# BL808 register map
File version: 0.1
Registers are access not given, no defined reset value unless marked. A register's access mark holds for its fields unless they carry their own. Offsets are from the block's base; [hi:lo] are bit positions.

## MM_GLB_CLK_RST
Base 0x30007000
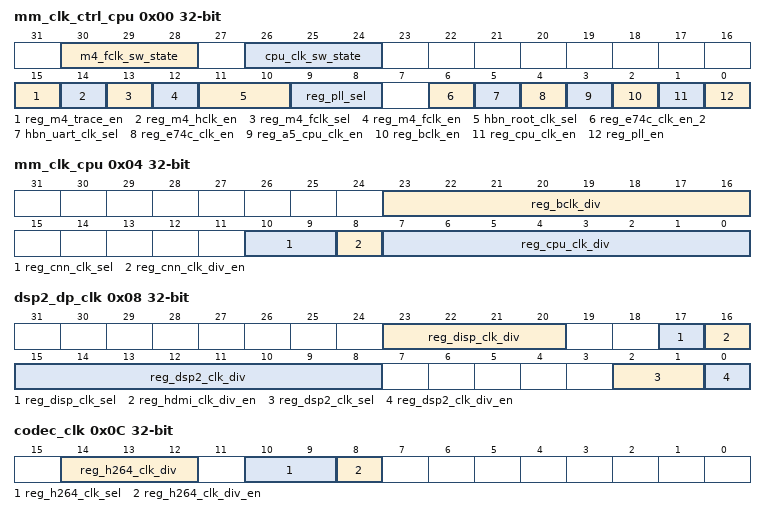
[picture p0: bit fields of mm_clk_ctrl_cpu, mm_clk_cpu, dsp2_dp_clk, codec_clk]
0x00 mm_clk_ctrl_cpu
  [30:28] m4_fclk_sw_state ro, [26:24] cpu_clk_sw_state ro, [15] reg_m4_trace_en rw, [14] reg_m4_hclk_en rw, [13] reg_m4_fclk_sel rw, [12] reg_m4_fclk_en rw, [11:10] hbn_root_clk_sel rw, [9:8] reg_pll_sel rw, [6] reg_e74c_clk_en_2 rw, [5] hbn_uart_clk_sel rw, [4] reg_e74c_clk_en rw, [3] reg_a5_cpu_clk_en rw, [2] reg_bclk_en rw, [1] reg_cpu_clk_en rw, [0] reg_pll_en rw
0x04 mm_clk_cpu
  [23:16] reg_bclk_div rw, [10:9] reg_cnn_clk_sel rw, [8] reg_cnn_clk_div_en rw, [7:0] reg_cpu_clk_div rw
0x08 dsp2_dp_clk
  [23:20] reg_disp_clk_div rw, [17] reg_disp_clk_sel rw, [16] reg_hdmi_clk_div_en rw, [15:8] reg_dsp2_clk_div rw, [2:1] reg_dsp2_clk_sel rw, [0] reg_dsp2_clk_div_en rw
0x0C codec_clk
  [14:12] reg_h264_clk_div, [10:9] reg_h264_clk_sel rw, [8] reg_h264_clk_div_en rw
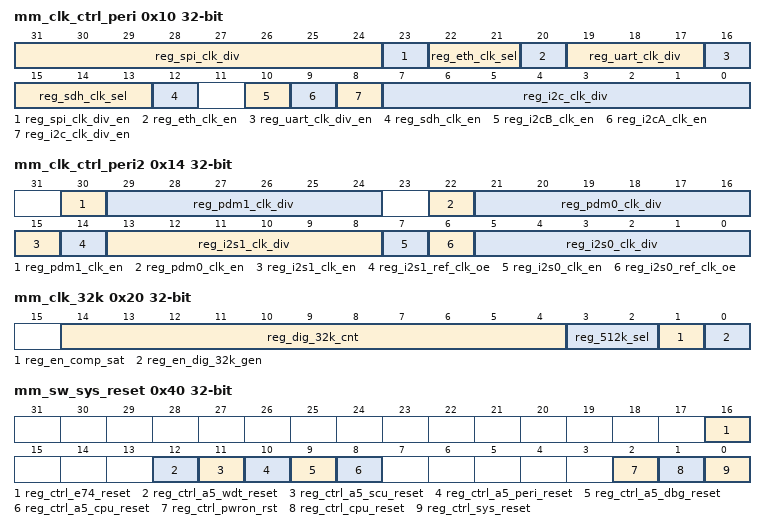
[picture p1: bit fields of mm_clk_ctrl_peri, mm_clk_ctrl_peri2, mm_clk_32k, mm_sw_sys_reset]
0x10 mm_clk_ctrl_peri
  [31:24] reg_spi_clk_div rw, [23] reg_spi_clk_div_en rw, [22:21] reg_eth_clk_sel rw, [20] reg_eth_clk_en rw, [19:17] reg_uart_clk_div rw, [16] reg_uart_clk_div_en rw, [15:13] reg_sdh_clk_sel rw, [12] reg_sdh_clk_en rw, [10] reg_i2cB_clk_en rw, [9] reg_i2cA_clk_en rw, [8] reg_i2c_clk_div_en rw, [7:0] reg_i2c_clk_div rw
0x14 mm_clk_ctrl_peri2
  [30] reg_pdm1_clk_en rw, [29:24] reg_pdm1_clk_div rw, [22] reg_pdm0_clk_en rw, [21:16] reg_pdm0_clk_div rw, [15] reg_i2s1_clk_en rw, [14] reg_i2s1_ref_clk_oe rw, [13:8] reg_i2s1_clk_div rw, [7] reg_i2s0_clk_en rw, [6] reg_i2s0_ref_clk_oe rw, [5:0] reg_i2s0_clk_div rw
0x20 mm_clk_32k
  [14:4] reg_dig_32k_cnt rw, [3:2] reg_512k_sel rw, [1] reg_en_comp_sat rw, [0] reg_en_dig_32k_gen rw
0x40 mm_sw_sys_reset
  [16] reg_ctrl_e74_reset rw, [12] reg_ctrl_a5_wdt_reset rw, [11] reg_ctrl_a5_scu_reset rw, [10] reg_ctrl_a5_peri_reset rw, [9] reg_ctrl_a5_dbg_reset rw, [8] reg_ctrl_a5_cpu_reset rw, [2] reg_ctrl_pwron_rst rw, [1] reg_ctrl_cpu_reset rw, [0] reg_ctrl_sys_reset rw
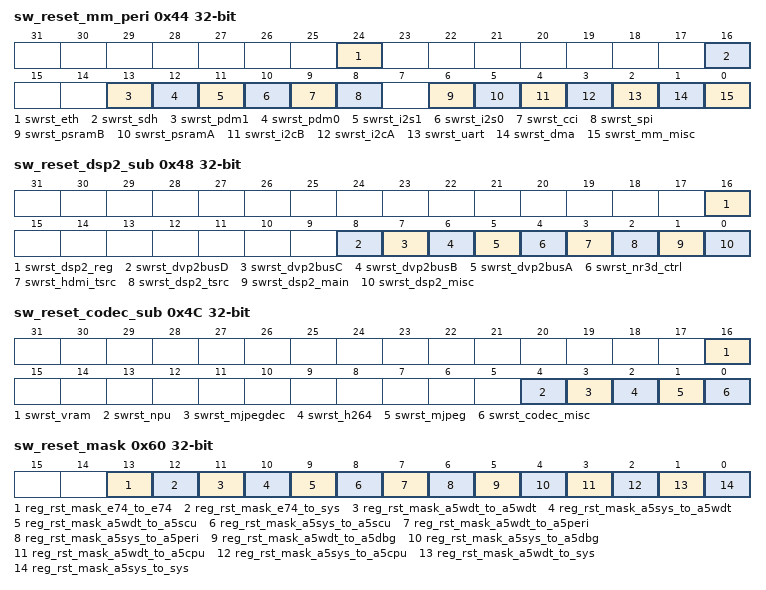
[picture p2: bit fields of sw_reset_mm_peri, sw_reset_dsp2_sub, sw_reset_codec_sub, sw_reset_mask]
0x44 sw_reset_mm_peri
  [24] swrst_eth rw, [16] swrst_sdh rw, [13] swrst_pdm1 rw, [12] swrst_pdm0 rw, [11] swrst_i2s1 rw, [10] swrst_i2s0 rw, [9] swrst_cci rw, [8] swrst_spi rw, [6] swrst_psramB rw, [5] swrst_psramA rw, [4] swrst_i2cB rw, [3] swrst_i2cA rw, [2] swrst_uart rw, [1] swrst_dma rw, [0] swrst_mm_misc rw
0x48 sw_reset_dsp2_sub
  [16] swrst_dsp2_reg rw, [8] swrst_dvp2busD rw, [7] swrst_dvp2busC rw, [6] swrst_dvp2busB rw, [5] swrst_dvp2busA rw, [4] swrst_nr3d_ctrl rw, [3] swrst_hdmi_tsrc rw, [2] swrst_dsp2_tsrc rw, [1] swrst_dsp2_main rw, [0] swrst_dsp2_misc rw
0x4C sw_reset_codec_sub
  [16] swrst_vram rw, [4] swrst_npu rw, [3] swrst_mjpegdec rw, [2] swrst_h264 rw, [1] swrst_mjpeg rw, [0] swrst_codec_misc rw
0x50 image_sensor_ctrl
  [0] rg_is_rst_n rw
0x60 sw_reset_mask
  [13] reg_rst_mask_e74_to_e74 rw, [12] reg_rst_mask_e74_to_sys rw, [11] reg_rst_mask_a5wdt_to_a5wdt rw, [10] reg_rst_mask_a5sys_to_a5wdt rw, [9] reg_rst_mask_a5wdt_to_a5scu rw, [8] reg_rst_mask_a5sys_to_a5scu rw, [7] reg_rst_mask_a5wdt_to_a5peri rw, [6] reg_rst_mask_a5sys_to_a5peri rw, [5] reg_rst_mask_a5wdt_to_a5dbg rw, [4] reg_rst_mask_a5sys_to_a5dbg rw, [3] reg_rst_mask_a5wdt_to_a5cpu rw, [2] reg_rst_mask_a5sys_to_a5cpu rw, [1] reg_rst_mask_a5wdt_to_sys rw, [0] reg_rst_mask_a5sys_to_sys rw
0x80 SYS_TICK_CFG
  [25:0] STCALIB rw
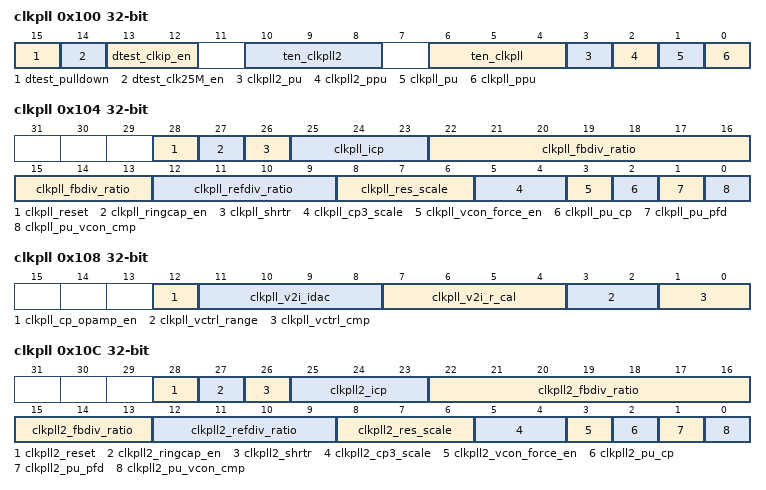
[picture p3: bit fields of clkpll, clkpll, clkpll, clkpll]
0x100 clkpll register 1
  [15] dtest_pulldown rw, [14] dtest_clk25M_en rw, [13:12] dtest_clkip_en rw, [10:8] ten_clkpll2 rw, [6:4] ten_clkpll rw, [3] clkpll2_pu rw, [2] clkpll2_ppu rw, [1] clkpll_pu rw, [0] clkpll_ppu rw
0x104 clkpll register 2
  [28] clkpll_reset rw, [27] clkpll_ringcap_en rw, [26] clkpll_shrtr rw, [25:23] clkpll_icp rw, [22:13] clkpll_fbdiv_ratio rw, [12:9] clkpll_refdiv_ratio rw, [8:6] clkpll_res_scale rw, [5:4] clkpll_cp3_scale rw, [3] clkpll_vcon_force_en rw, [2] clkpll_pu_cp rw, [1] clkpll_pu_pfd rw, [0] clkpll_pu_vcon_cmp rw
0x108 clkpll register 3
  [12] clkpll_cp_opamp_en rw, [11:8] clkpll_v2i_idac rw, [7:4] clkpll_v2i_r_cal rw, [3:2] clkpll_vctrl_range rw, [1:0] clkpll_vctrl_cmp ro
0x10C clkpll register 4
  [28] clkpll2_reset rw, [27] clkpll2_ringcap_en rw, [26] clkpll2_shrtr rw, [25:23] clkpll2_icp rw, [22:13] clkpll2_fbdiv_ratio rw, [12:9] clkpll2_refdiv_ratio rw, [8:6] clkpll2_res_scale rw, [5:4] clkpll2_cp3_scale rw, [3] clkpll2_vcon_force_en rw, [2] clkpll2_pu_cp rw, [1] clkpll2_pu_pfd rw, [0] clkpll2_pu_vcon_cmp rw
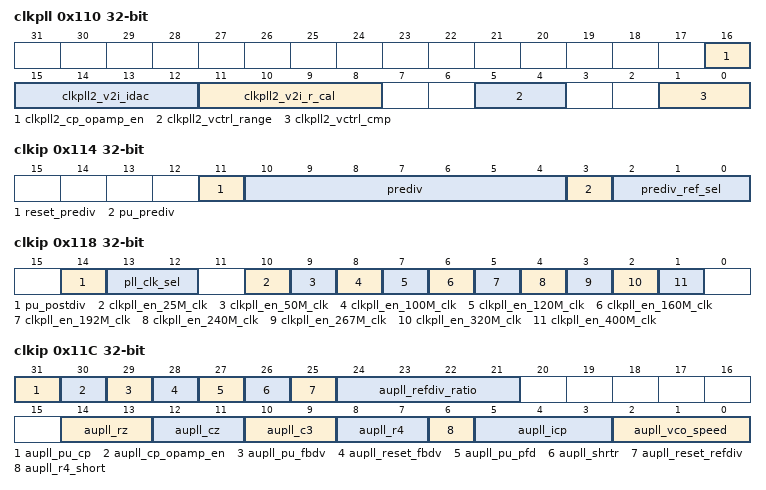
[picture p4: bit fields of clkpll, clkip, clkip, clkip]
0x110 clkpll register 5
  [16] clkpll2_cp_opamp_en rw, [15:12] clkpll2_v2i_idac rw, [11:8] clkpll2_v2i_r_cal rw, [5:4] clkpll2_vctrl_range rw, [1:0] clkpll2_vctrl_cmp ro
0x114 clkip prediv
  [11] reset_prediv rw, [10:4] prediv rw, [3] pu_prediv rw, [2:0] prediv_ref_sel rw
0x118 clkip postdiv
  [14] pu_postdiv rw, [13:12] pll_clk_sel rw, [10] clkpll_en_25M_clk rw, [9] clkpll_en_50M_clk rw, [8] clkpll_en_100M_clk rw, [7] clkpll_en_120M_clk rw, [6] clkpll_en_160M_clk rw, [5] clkpll_en_192M_clk rw, [4] clkpll_en_240M_clk rw, [3] clkpll_en_267M_clk rw, [2] clkpll_en_320M_clk rw, [1] clkpll_en_400M_clk rw
0x11C clkip aupll register 1
  [31] aupll_pu_cp rw, [30] aupll_cp_opamp_en rw, [29] aupll_pu_fbdv rw, [28] aupll_reset_fbdv rw, [27] aupll_pu_pfd rw, [26] aupll_shrtr rw, [25] aupll_reset_refdiv rw, [24:21] aupll_refdiv_ratio rw, [14:13] aupll_rz rw, [12:11] aupll_cz rw, [10:9] aupll_c3 rw, [8:7] aupll_r4 rw, [6] aupll_r4_short rw, [5:3] aupll_icp rw, [2:0] aupll_vco_speed rw
0x120 clkip aupll register 2
  [23:0] aupll_sdmin rw
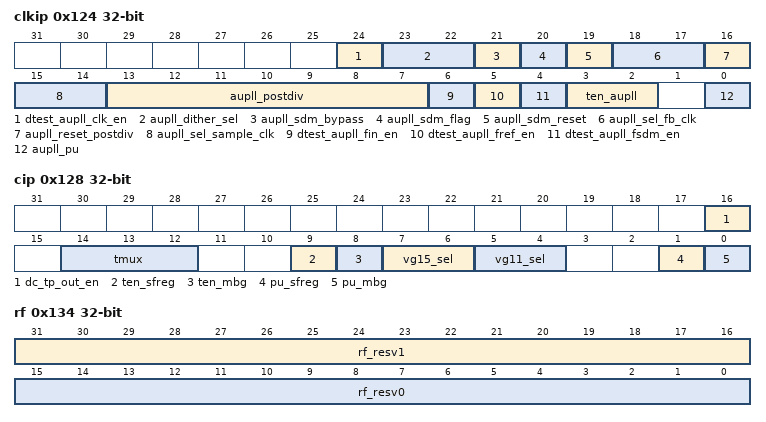
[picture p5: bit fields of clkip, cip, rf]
0x124 clkip aupll register 3
  [24] dtest_aupll_clk_en rw, [23:22] aupll_dither_sel rw, [21] aupll_sdm_bypass rw, [20] aupll_sdm_flag rw, [19] aupll_sdm_reset rw, [18:17] aupll_sel_fb_clk rw, [16] aupll_reset_postdiv rw, [15:14] aupll_sel_sample_clk rw, [13:7] aupll_postdiv rw, [6] dtest_aupll_fin_en rw, [5] dtest_aupll_fref_en rw, [4] dtest_aupll_fsdm_en rw, [3:2] ten_aupll rw, [0] aupll_pu rw
0x128 cip register
  [16] dc_tp_out_en rw, [14:12] tmux rw, [9] ten_sfreg rw, [8] ten_mbg rw, [7:6] vg15_sel rw, [5:4] vg11_sel rw, [1] pu_sfreg rw, [0] pu_mbg rw
0x12C ldo11 register 1 rw
  [31:0] ldo11_cfg0
0x130 ldo11 register 2 rw
  [31:0] ldo11_cfg1
0x134 rf reserved register rw
  [31:16] rf_resv1, [15:0] rf_resv0
0x138 rf reserved register ro
  [31:0] rf_out_resv
